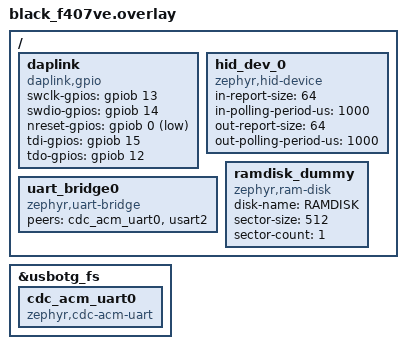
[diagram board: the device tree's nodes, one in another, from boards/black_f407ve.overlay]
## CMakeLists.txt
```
# SPDX-License-Identifier: Apache-2.0

cmake_minimum_required(VERSION 3.20.0)

find_package(Zephyr REQUIRED HINTS $ENV{ZEPHYR_BASE})
project(daplink-zephyr)

# Custom DTS bindings for daplink,gpio
set(DTS_ROOT ${CMAKE_CURRENT_SOURCE_DIR})

target_include_directories(app PRIVATE
    src
    src/dap
    src/usb
    src/hal
    src/flash
)

# Core sources (always compiled)
target_sources(app PRIVATE
    src/main.c
    src/hal/dap_gpio.c
    src/hal/dap_delay.c
    src/dap/DAP.c
    src/dap/SW_DP.c
    src/usb/usbd_context.c
    src/usb/hid_dap.c
)

# JTAG transport (optional; ~9KB Flash)
if (CONFIG_DAPLINK_JTAG)
target_sources(app PRIVATE
    src/dap/JTAG_DP.c
)
endif()

# CMSIS-DAP SWO capture over a UART (optional; needs a daplink,swo DT node)
if (CONFIG_DAPLINK_SWO)
target_sources(app PRIVATE
    src/hal/dap_swo.c
)
endif()

# SEGGER RTT / option bytes over CMSIS-DAP vendor commands (optional)
if (CONFIG_DAPLINK_RTT)
target_sources(app PRIVATE
    src/flash/rtt.c
)
endif()
if (CONFIG_DAPLINK_RTT OR CONFIG_DAPLINK_OPTION_BYTES OR CONFIG_DAPLINK_VENDOR_REBOOT OR CONFIG_DAPLINK_SPI_FLASH OR CONFIG_DAPLINK_SWO_ITM)
target_sources(app PRIVATE
    src/dap/dap_vendor.c
)
endif()

# SWO ITM software decoder (optional)
if (CONFIG_DAPLINK_SWO_ITM)
target_sources(app PRIVATE
    src/hal/swo_itm.c
)
endif()

# Probe-side SPI NOR flash (optional)
if (CONFIG_DAPLINK_SPI_FLASH)
target_sources(app PRIVATE
    src/flash/spi_flash.c
    src/flash/sfdp.c
)
endif()

# MSC drag-and-drop flash programming (optional, requires ~32KB RAM)
if (CONFIG_DAPLINK_MSC_FLASH)
target_sources(app PRIVATE
    src/flash/flash_blob.h
    src/flash/target_probe.h
    src/flash/target_detect.c
    src/flash/flash_mem.c
    src/flash/swd_host.c
    src/flash/intelhex.c
    src/flash/flash_manager.c
    src/flash/vfs_disk.c
)

if (CONFIG_DAPLINK_TARGET_STM32)
target_sources(app PRIVATE
    src/flash/target_stm32_detect.c
    src/flash/target_stm32f0.c
    src/flash/target_stm32f1.c
    src/flash/target_stm32f2.c
    src/flash/target_stm32f3.c
    src/flash/target_stm32f4.c
    src/flash/target_stm32f429.c
    src/flash/target_stm32f7.c
    src/flash/target_stm32l0.c
    src/flash/target_stm32l1.c
    src/flash/target_stm32l4.c
    src/flash/flash_native_stm32.c
    src/flash/flash_native_stm32l4.c
)
endif()

if (CONFIG_DAPLINK_TARGET_MISC)
target_sources(app PRIVATE
    src/flash/target_simple.c
    src/flash/target_nrf52.c
    src/flash/target_lpc1768.c
    src/flash/flash_native_nrf52.c
)
endif()

if (CONFIG_DAPLINK_RISCV)
target_sources(app PRIVATE
    src/flash/riscv_probe.h
    src/flash/target_riscv.c
    src/flash/target_riscv32.c
    src/flash/riscv_jtag_dtm.c
    src/flash/riscv_adi_dtm.c
    src/flash/riscv_gateway_dtm.c
    src/flash/riscv_dm.c
)
endif()
endif()

# Suppress warnings for DAPLink core files
set_source_files_properties(
    src/dap/DAP.c
    src/dap/SW_DP.c
    src/dap/JTAG_DP.c
    PROPERTIES
    COMPILE_FLAGS "-Wno-unused-parameter -Wno-sign-compare -Wno-unused-variable"
)
```

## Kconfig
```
# SPDX-License-Identifier: Apache-2.0
#
# DAPLink application Kconfig - extends Zephyr defaults
#

source "Kconfig.zephyr"

config DAPLINK_MSC_FLASH
	bool "Enable MSC drag-and-drop flash programming"
	default y if DISK_ACCESS
	help
	  Enable virtual FAT16 disk for drag-and-drop firmware flashing.
	  Requires ~32KB RAM for the in-memory disk image. Disable this
	  option for resource-constrained targets (e.g. STM32F103C8T6).

	  When enabled, you should also enable CONFIG_USBD_MSC_CLASS and
	  CONFIG_DISK_ACCESS in your board configuration.

config DAPLINK_JTAG
	bool "Enable JTAG transport (in addition to SWD)"
	default y
	help
	  Compile the JTAG DP I/O (JTAG_DP.c) into the CMSIS-DAP core and
	  advertise JTAG in DAP_Capabilities. Adds roughly 9KB of Flash.
	  Disable this on resource-constrained probes (e.g. 64KB Flash
	  Blue Pill) to keep SWD-only operation.

config DAPLINK_TARGET_STM32
	bool "Enable STM32 target family support"
	default y
	depends on DAPLINK_MSC_FLASH
	help
	  STM32 target detection (DBGMCU DEV_ID) and register-level flash
	  drivers (F0/F1/F2/F3/F4/F429/L4). Disable to save Flash on small
	  probes that only need a single family.

config DAPLINK_TARGET_MISC
	bool "Enable nRF / LPC target support"
	default y
	depends on DAPLINK_MSC_FLASH
	help
	  Nordic nRF52832 and NXP LPC1768 targets (detected by DP IDCODE;
	  nRF uses the register-level NVMC flash driver).

config DAPLINK_RTT
	bool "Enable SEGGER RTT over CMSIS-DAP vendor commands"
	default n
	depends on DAPLINK_MSC_FLASH
	help
	  Discover the target's SEGGER RTT control block over SWD and expose
	  its ring buffers through CMSIS-DAP vendor commands (0x80). Requires
	  a host-side client that speaks this vendor protocol (pyOCD plugin
	  or a small script); there is no standard RTT-over-CMSIS-DAP yet.

config DAPLINK_OPTION_BYTES
	bool "Enable STM32 option-byte access over CMSIS-DAP vendor commands"
	default n
	depends on DAPLINK_MSC_FLASH
	help
	  Read and program STM32 option bytes (RDP/WRP/BOR etc.) through
	  CMSIS-DAP vendor command 0x80 sub-commands 0x10/0x11. Currently
	  implemented for the STM32F4 flash controller. Programming option
	  bytes triggers a system reset (OBL_LAUNCH).

config DAPLINK_VENDOR_REBOOT
	bool "Enable probe reboot vendor command"
	default n
	select REBOOT
	help
	  Expose CMSIS-DAP vendor command 0x80 sub-command 0x20 which reboots
	  the probe. Combined with an MCUboot bootloader (see sysbuild.conf)
	  this lets a host trigger a firmware update / boot into the new image.

config DAPLINK_RISCV
	bool "Enable experimental RISC-V JTAG detection"
	default n
	depends on DAPLINK_JTAG && DAPLINK_MSC_FLASH
	help
	  Reset the JTAG TAP and read the chain IDCODE as a first step towards
	  RISC-V support. This is DETECTION ONLY: it does not provide DTM/DMI
	  access, register/memory access or flash programming yet.

config DAPLINK_SPI_FLASH
	bool "Enable probe-side SPI NOR flash programming"
	default n
	depends on SPI
	help
	  Drive a SPI NOR flash connected to the probe (not the target) via a
	  Zephyr SPI controller. JEDEC ID / SFDP are used to discover geometry;
	  read/erase/program are exposed through CMSIS-DAP vendor commands
	  (0x80 sub-commands 0x30..0x34). Requires a devicetree node:

	    &spi1 {
	        spiflash: spiflash@0 {
	            compatible = "daplink,spi-flash";
	            reg = <0>;
	            spi-max-frequency = <8000000>;
	        };
	    };

config DAPLINK_SWO_ITM
	bool "Enable SWO ITM software decoding"
	default n
	depends on DAPLINK_SWO
	help
	  Decode ITM/SWIT packets from the captured SWO UART stream and expose
	  the decoded channel data through CMSIS-DAP vendor commands (0x80
	  sub-commands 0x40..0x42). Manchester-encoded SWO capture is NOT
	  implemented (it requires timer input-capture hardware on the SWO pin).

config DAPLINK_SWO
	bool "Enable CMSIS-DAP SWO (UART) capture"
	default n
	depends on SERIAL
	help
	  Implement the CMSIS-DAP ID_DAP_SWO_* commands backed by a Zephyr
	  UART capturing the target's SWO / ITM-as-UART output. This lets
	  pyOCD/OpenOCD stream target printf over the same CMSIS-DAP link.

	  Requires a devicetree node:

	    swo0: swo0 {
	        compatible = "daplink,swo";
	        uart = <&usart1>;   /* UART whose RX pin is wired to target SWO */
	    };

	  Off by default because it needs a dedicated probe RX pin wired to
	  the target's SWO output.
```

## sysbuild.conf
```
# Black Magic Debug - Zephyr (daplink-zephyr) OTA / DFU via MCUboot.
#
# This file is only used for sysbuild builds:
#   west build --sysbuild -b black_f407ve .
#
# MCUboot provides serial recovery and/or USB DFU for updating the probe.
# The normal (single-image) build ignores this file.

SB_CONFIG_BOOTLOADER_MCUBOOT=y
SB_CONFIG_MCUBOOT_MODE_SWAP_SCRATCH=y
```

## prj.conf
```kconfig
# USB 新栈
CONFIG_USB_DEVICE_STACK_NEXT=y
CONFIG_UDC_DRIVER=y

# HID (CMSIS-DAP)
CONFIG_USBD_HID_SUPPORT=y

# CDC ACM (Phase 2)
CONFIG_USBD_CDC_ACM_CLASS=y
CONFIG_CDC_ACM_SERIAL_INITIALIZE_AT_BOOT=n
CONFIG_UART_LINE_CTRL=y
CONFIG_UART_USE_RUNTIME_CONFIGURE=y

# UART Bridge (CDC <-> target UART)
CONFIG_UART_BRIDGE=y

# MSC drag-and-drop flash (enabled by default, boards can override)
CONFIG_DISK_ACCESS=y
CONFIG_USBD_MSC_CLASS=y
CONFIG_DAPLINK_MSC_FLASH=y

# 基础功能
CONFIG_GPIO=y
CONFIG_SERIAL=y

# 日志
CONFIG_LOG=y

# 栈和堆
CONFIG_MAIN_STACK_SIZE=2048
CONFIG_HEAP_MEM_POOL_SIZE=4096
```

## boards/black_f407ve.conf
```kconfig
# Black F407VE - full DAPLink configuration overrides
# Inherits defaults from prj.conf, only overrides here.

# Log level (INFO)
CONFIG_LOG_DEFAULT_LEVEL=2
```

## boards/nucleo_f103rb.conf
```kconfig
# NUCLEO-F103RB (STM32F103RB, 128KB Flash / 20KB RAM)
# Minimal DAPLink configuration: HID (CMSIS-DAP) + CDC, no MSC.
#
# The default prj.conf enables the 32KB in-RAM MSC disk image, which does not
# fit in the F103's 20KB of RAM. Disable it here (same reason stm32_min_dev
# disables MSC). This board/overlay exists for build verification.

CONFIG_USB_DEVICE_STACK_NEXT=y
CONFIG_UDC_DRIVER=y

# HID (CMSIS-DAP)
CONFIG_USBD_HID_SUPPORT=y

# CDC ACM (serial bridge)
CONFIG_USBD_CDC_ACM_CLASS=y
CONFIG_CDC_ACM_SERIAL_INITIALIZE_AT_BOOT=n
CONFIG_UART_LINE_CTRL=y
CONFIG_UART_USE_RUNTIME_CONFIGURE=y
CONFIG_UART_BRIDGE=y

# Disable MSC drag-and-drop (resource constrained, 20KB RAM)
CONFIG_DAPLINK_MSC_FLASH=n
CONFIG_USBD_MSC_CLASS=n
CONFIG_DISK_ACCESS=n

# Disable JTAG (Flash constrained, SWD only)
CONFIG_DAPLINK_JTAG=n

# Basic
CONFIG_GPIO=y
CONFIG_SERIAL=y

# Aggressive size optimization
CONFIG_MAIN_STACK_SIZE=1024
CONFIG_HEAP_MEM_POOL_SIZE=256
CONFIG_SYSTEM_WORKQUEUE_STACK_SIZE=512

# Disable logging/console (saves Flash + RAM)
CONFIG_LOG=n
CONFIG_CONSOLE=n
CONFIG_UART_CONSOLE=n
CONFIG_COMPILER_OPT="-Os"
```

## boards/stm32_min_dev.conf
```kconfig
# Blue Pill (STM32F103C8T6) - minimal DAPLink configuration
# HID (CMSIS-DAP) only, optimized for 64KB Flash / 20KB RAM

CONFIG_USB_DEVICE_STACK_NEXT=y
CONFIG_UDC_DRIVER=y

# HID (CMSIS-DAP)
CONFIG_USBD_HID_SUPPORT=y

# CDC ACM (serial bridge)
CONFIG_USBD_CDC_ACM_CLASS=y
CONFIG_CDC_ACM_SERIAL_INITIALIZE_AT_BOOT=n
CONFIG_UART_LINE_CTRL=y
CONFIG_UART_USE_RUNTIME_CONFIGURE=y

# UART Bridge
CONFIG_UART_BRIDGE=y

# Disable MSC drag-and-drop (resource constrained)
CONFIG_DAPLINK_MSC_FLASH=n
CONFIG_USBD_MSC_CLASS=n
CONFIG_DISK_ACCESS=n

# Disable JTAG (Flash constrained, SWD only)
CONFIG_DAPLINK_JTAG=n

# Basic
CONFIG_GPIO=y
CONFIG_SERIAL=y

# Aggressive size optimization
CONFIG_MAIN_STACK_SIZE=1024
CONFIG_HEAP_MEM_POOL_SIZE=256
CONFIG_SYSTEM_WORKQUEUE_STACK_SIZE=512

# Disable logging (saves ~5-8KB Flash + ~2KB RAM)
CONFIG_LOG=n

# Disable console (saves ~2KB Flash)
CONFIG_CONSOLE=n
CONFIG_UART_CONSOLE=n

# Optimize for size
CONFIG_COMPILER_OPT="-Os"
```

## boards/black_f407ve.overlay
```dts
/*
 * DAPLink Zephyr - Black F407VE Board Overlay
 *
 * Adds: HID debug, CDC ACM UART bridge, MSC (VFS drag-and-drop)
 * Board DTS already enables USB OTG FS (zephyr_udc0).
 */

/ {
	/* SWD debug probe GPIO pins */
	daplink: daplink {
		compatible = "daplink,gpio";

		swclk-gpios = <&gpiob 13 0>;
		swdio-gpios = <&gpiob 14 0>;
		nreset-gpios = <&gpiob 0 (GPIO_OPEN_DRAIN | GPIO_ACTIVE_LOW)>;
		/* JTAG: TCK=PB13, TMS=PB14 (reuse SWCLK/SWDIO) */
		tdi-gpios = <&gpiob 15 0>;
		tdo-gpios = <&gpiob 12 0>;
	};

	/* HID device for CMSIS-DAP */
	hid_dev_0: hid_dev_0 {
		compatible = "zephyr,hid-device";
		in-report-size = <64>;
		in-polling-period-us = <1000>;
		out-report-size = <64>;
		out-polling-period-us = <1000>;
	};

	/* UART bridge: CDC ACM <-> target USART2 (PA2/PA3) */
	uart_bridge0 {
		compatible = "zephyr,uart-bridge";
		peers = <&cdc_acm_uart0 &usart2>;
	};

	/*
	 * Dummy RAM disk: ensures drivers__disk library has sources.
	 * The actual MSC backend is the custom VFS driver (vfs_disk.c).
	 * Uses disk-name "RAMDISK" (not "DAPLINK") to avoid conflicts.
	 */
	ramdisk_dummy {
		compatible = "zephyr,ram-disk";
		disk-name = "RAMDISK";
		sector-size = <512>;
		sector-count = <1>;
	};
};

/* CDC ACM UART instance (child of USB controller) */
&usbotg_fs {
	cdc_acm_uart0: cdc_acm_uart0 {
		compatible = "zephyr,cdc-acm-uart";
	};
};
```

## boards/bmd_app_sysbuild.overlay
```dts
/*
 * Application-side MCUboot partition layout.
 * Applied to the main image only when building with --sysbuild (see
 * sysbuild.cmake). Places the application in slot0.
 */

#include "bmd_partitions.dtsi"

/ {
	chosen {
		zephyr,code-partition = &slot0_partition;
	};
};
```

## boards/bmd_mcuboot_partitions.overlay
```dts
/*
 * MCUboot bootloader image partition layout.
 * Applied to the MCUboot image only (see sysbuild.cmake / build command).
 */

#include "bmd_partitions.dtsi"
```

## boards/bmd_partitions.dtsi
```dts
/*
 * Shared MCUboot flash partition layout (512 KB STM32F407VE).
 *
 * Aligned to the F4 sector map (4x16K + 1x64K + 3x128K = sectors 0..7):
 *   sector 0-4 (0x00000-0x1FFFF, 128K) -> mcuboot bootloader
 *   sector 5   (0x20000-0x3FFFF, 128K) -> slot0 (primary)
 *   sector 6   (0x40000-0x5FFFF, 128K) -> slot1 (secondary)
 *   sector 7   (0x60000-0x7FFFF, 128K) -> scratch (>= largest sector)
 *
 * Included by boards/bmd_app_sysbuild.overlay and
 * boards/bmd_mcuboot_partitions.overlay.
 */

&flash0 {
	partitions {
		compatible = "fixed-partitions";
		#address-cells = <1>;
		#size-cells = <1>;

		boot_partition: partition@0 {
			label = "mcuboot";
			reg = <0x00000000 0x00020000>;
			read-only;
		};

		slot0_partition: partition@20000 {
			label = "image-0";
			reg = <0x00020000 0x00020000>;
		};

		slot1_partition: partition@40000 {
			label = "image-1";
			reg = <0x00040000 0x00020000>;
		};

		scratch_partition: partition@60000 {
			label = "image-scratch";
			reg = <0x00060000 0x00020000>;
		};
	};
};
```

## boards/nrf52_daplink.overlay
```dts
/*
 * DAPLink Zephyr Board Overlay - nRF52840 Reference
 */

/ {
	daplink: daplink {
		compatible = "daplink,gpio";
		swclk-gpios = <&gpio0 11 0>;
		swdio-gpios = <&gpio0 12 0>;
		nreset-gpios = <&gpio0 13 (GPIO_OPEN_DRAIN | GPIO_ACTIVE_LOW)>;
	};
};

/ {
	daplink_hid: hid_dev {
		compatible = "zephyr,hid-device";
		in-report-size = <64>;
		in-polling-period-us = <1000>;
		out-report-size = <64>;
		out-polling-period-us = <1000>;
	};
};
```

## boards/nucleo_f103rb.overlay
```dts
/*
 * DAPLink Zephyr - NUCLEO-F103RB Board Overlay
 *
 * Enables USB device controller and configures HID + SWD GPIO.
 * Note: NUCLEO-F103RB does not expose target USB connector.
 * This overlay is for build verification / firmware development.
 */

/* Enable USB device controller (PA11/PA12 fixed-function pins) */
zephyr_udc0: &usb {
	status = "okay";
};

/ {
	/* DAPLink SWD GPIO pins */
	daplink: daplink {
		compatible = "daplink,gpio";

		/* SWCLK - push-pull output (PB13) */
		swclk-gpios = <&gpiob 13 0>;

		/* SWDIO - bidirectional (PB14) */
		swdio-gpios = <&gpiob 14 0>;

		/* Target nRESET - open drain (PB0) */
		nreset-gpios = <&gpiob 0 (GPIO_OPEN_DRAIN | GPIO_ACTIVE_LOW)>;
	};

	/* HID device node for DAP interface */
	hid_dev_0: hid_dev_0 {
		compatible = "zephyr,hid-device";
		in-report-size = <64>;
		in-polling-period-us = <1000>;
		out-report-size = <64>;
		out-polling-period-us = <1000>;
	};
};
```

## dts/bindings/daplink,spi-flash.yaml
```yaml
description: |
  Probe-side SPI NOR flash.

  Place the node under a SPI controller and point `cs-gpios` at the flash
  chip-select. The driver reads JEDEC ID / SFDP to discover geometry and
  exposes read/erase/program via CMSIS-DAP vendor commands.

compatible: "daplink,spi-flash"

properties:
  reg:
    type: int
    required: true
    description: Chip-select index on the SPI bus.
  spi-max-frequency:
    type: int
    required: true
    description: Maximum SPI clock in Hz.
  jedec-id:
    type: int
    description: Optional expected JEDEC ID (0x00BBCC where BB=vendor, CC=type).
```

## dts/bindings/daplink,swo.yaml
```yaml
description: |
  CMSIS-DAP SWO capture source.

  Points at the UART whose RX pin is connected to the target's SWO (single
  wire output / ITM-as-UART) line. The DAPLink application configures this
  UART to the requested SWO baud rate and streams the captured bytes through
  the CMSIS-DAP ID_DAP_SWO_* commands.

compatible: "daplink,swo"

properties:
  uart:
    type: phandle
    required: true
    description: UART device used to capture the target SWO stream.
```

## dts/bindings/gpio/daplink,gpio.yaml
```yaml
# SPDX-License-Identifier: Apache-2.0
#
# DAPLink GPIO binding - SWD/JTAG debug probe pins

description: DAPLink SWD/JTAG debug probe GPIO pins

compatible: "daplink,gpio"

properties:
  swclk-gpios:
    type: phandle-array
    required: true
    description: SWCLK/TCK output pin

  swdio-gpios:
    type: phandle-array
    required: true
    description: SWDIO/TMS bidirectional data pin

  swdio-in-gpios:
    type: phandle-array
    required: false
    description: Optional separate SWDIO input pin

  nreset-gpios:
    type: phandle-array
    required: false
    description: Target nRESET pin (open-drain)

  tdi-gpios:
    type: phandle-array
    required: false
    description: JTAG TDI output pin (optional; enables JTAG mode)

  tdo-gpios:
    type: phandle-array
    required: false
    description: JTAG TDO input pin (optional; enables JTAG mode)
```

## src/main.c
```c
/*
 * SPDX-License-Identifier: Apache-2.0
 *
 * DAPLink Zephyr Port - CMSIS-DAP Debug Probe
 *
 * Phase 1: HID debugging interface
 * Phase 2: CDC ACM serial bridge
 * Phase 3: MSC drag-and-drop flash programming (optional)
 */

#include <zephyr/kernel.h>
#include <zephyr/logging/log.h>

#include "dap_gpio.h"
#include "dap_delay.h"
#include "DAP.h"
#include "usbd_context.h"
#include "hid_dap.h"

#ifdef CONFIG_DAPLINK_MSC_FLASH
#include "vfs_disk.h"
#endif

LOG_MODULE_REGISTER(daplink, LOG_LEVEL_INF);

int main(void)
{
	int ret;

	LOG_INF("DAPLink Zephyr starting...");

	/* Step 1: Initialize HAL */
	ret = dap_gpio_init();
	if (ret != 0) {
		LOG_ERR("GPIO init failed: %d", ret);
		return ret;
	}

	dap_delay_init();

	/* Step 2: Initialize DAP core */
	DAP_Setup();
	LOG_INF("CMSIS-DAP initialized");

#ifdef CONFIG_DAPLINK_MSC_FLASH
	/* Step 3: Initialize VFS disk (must be before USB) */
	ret = vfs_disk_init();
	if (ret != 0) {
		LOG_ERR("VFS disk init failed: %d", ret);
		return ret;
	}
#endif

	/* Step 4: Initialize HID-DAP adapter */
	ret = hid_dap_init();
	if (ret != 0) {
		LOG_ERR("HID-DAP init failed: %d", ret);
		return ret;
	}

	/* Step 5: Initialize USB device */
	ret = daplink_usbd_init();
	if (ret != 0) {
		LOG_ERR("USB device init failed: %d", ret);
		return ret;
	}

	/* Step 6: Enable USB */
	struct usbd_context *usbd = daplink_usbd_ctx();

	if (!usbd_can_detect_vbus(usbd)) {
		ret = usbd_enable(usbd);
		if (ret != 0) {
			LOG_ERR("USB enable failed: %d", ret);
			return ret;
		}
	}

#ifdef CONFIG_DAPLINK_MSC_FLASH
	LOG_INF("DAPLink ready - HID + CDC + MSC active");
#else
	LOG_INF("DAPLink ready - HID + CDC active");
#endif

	while (true) {
		k_sleep(K_MSEC(1000));
	}

	return 0;
}
```
